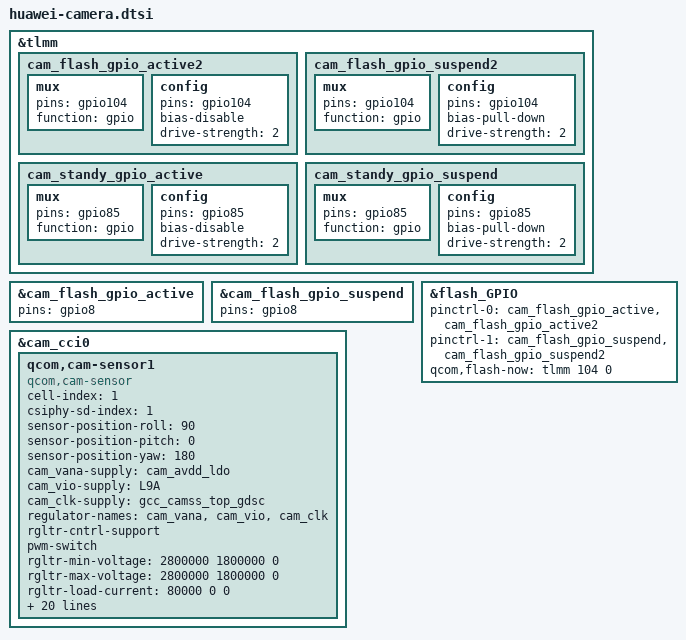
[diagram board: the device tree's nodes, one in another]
&tlmm{
	cam_flash_gpio_active2: cam_flash_gpio_active2 {
		mux {
			pins = "gpio104";
			function = "gpio";
		};

		config {
			pins = "gpio104";
			bias-disable; /* No PULL */
			drive-strength = <2>; /* 2 MA */
		};
	};

	cam_flash_gpio_suspend2: cam_flash_gpio_suspend2 {
		mux {
			pins = "gpio104";
			function = "gpio";
		};

		config {
			pins = "gpio104";
			bias-pull-down; /* PULL DOWN */
			drive-strength = <2>; /* 2 MA */
		};
	};

	cam_standy_gpio_active: cam_standy_gpio_active {
		mux {
			pins = "gpio85";
			function = "gpio";
		};

		config {
			pins = "gpio85";
			bias-disable; /* No PULL */
			drive-strength = <2>; /* 2 MA */
		};
	};

	cam_standy_gpio_suspend: cam_standy_gpio_suspend {
		mux {
			pins = "gpio85";
			function = "gpio";
		};

		config {
			pins = "gpio85";
			bias-pull-down; /* PULL DOWN */
			drive-strength = <2>; /* 2 MA */
		};
	};
};

&cam_flash_gpio_active {
		pins = "gpio8";
};

&cam_flash_gpio_suspend {
		pins = "gpio8";
};

&flash_GPIO{
	pinctrl-0 = <&cam_flash_gpio_active
			&cam_flash_gpio_active2>;
	pinctrl-1 = <&cam_flash_gpio_suspend
			&cam_flash_gpio_suspend2>;
	qcom,flash-now = <&tlmm 104 0>;
};

&cam_cci0 {
	//Rear Aux depth
	qcom,cam-sensor1 {
		cell-index = <1>;
		compatible = "qcom,cam-sensor";
		csiphy-sd-index = <1>;
		sensor-position-roll = <90>;
		sensor-position-pitch = <0>;
		sensor-position-yaw = <180>;
		cam_vana-supply = <&cam_avdd_ldo>;
		cam_vio-supply = <&L9A>;
		cam_clk-supply = <&gcc_camss_top_gdsc>;
		regulator-names = "cam_vana", "cam_vio", "cam_clk";
		rgltr-cntrl-support;
		pwm-switch;
		rgltr-min-voltage = <2800000 1800000 0>;
		rgltr-max-voltage = <2800000 1800000 0>;
		rgltr-load-current = <80000 0 0>;
		gpio-no-mux = <0>;
		pinctrl-names = "cam_default", "cam_suspend";
		pinctrl-0 = <&cam_sensor_mclk3_active
				&cam_sensor_rear2_reset_active
				&cam_standy_gpio_active>;
		pinctrl-1 = <&cam_sensor_mclk3_suspend
				&cam_sensor_rear2_reset_suspend
				&cam_standy_gpio_suspend>;
		gpios = <&tlmm 28 0>,
			<&tlmm 66 0>,
			<&tlmm 85 0>;
		gpio-reset = <1>;
		gpio-standby = <2>;
		gpio-req-tbl-num = <0 1 2>;
		gpio-req-tbl-flags = <1 0 0>;
		gpio-req-tbl-label = "CAMIF_MCLK1",
						"CAM_RESET1",
						"CAM_STANDBY";
		sensor-mode = <0>;
		cci-master = <0>;
		status = "ok";
		clocks = <&gcc GCC_CAMSS_MCLK3_CLK>;
		clock-names = "cam_clk";
		clock-cntl-level = "turbo";
		clock-rates = <19200000>;
		ic_position = <2>; /* CAMERA_POSITION_REAR_SECOND */
	};
};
